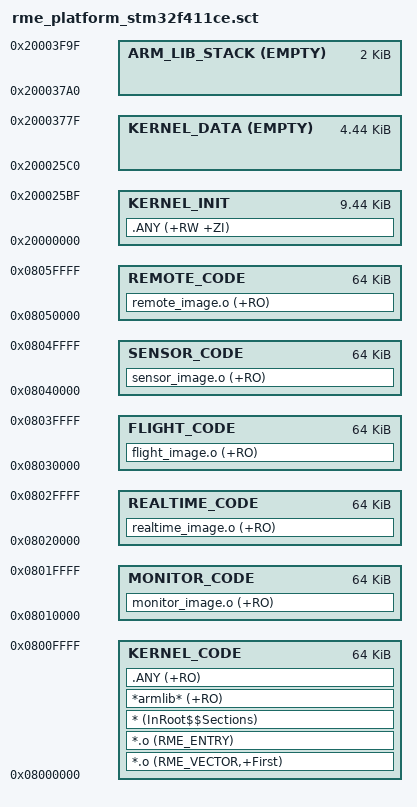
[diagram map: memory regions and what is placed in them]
;******************************************************************************
;Filename    : rme_platform_stm32f411ce.sct
;Author      : The RVM project generator.
;Date        : 21/05/2025 22:33:52
;Licence     : Unlicense; see COPYING for details.
;Description : The scatter file for ARMv7-M layout. This file is intended
;              to be used with STM32F411CE.
;******************************************************************************

;Kernel ***********************************************************************
KERNEL 0x8000000 0x10000
{
    ;Kernel code segment
    KERNEL_CODE 0x8000000 0x10000
    {
        ;The vector table
        *.o                            (RME_VECTOR,+First)
        ;The entry
        *.o                            (RME_ENTRY)
        ;The lib code copying code
        *                              (InRoot$$Sections)
        ;The ARM C library code - all of them is here
        *armlib*                       (+RO)
        ;The kernel code section
        .ANY                           (+RO)
    }

    ;Statically allocated kernel data segment
    KERNEL_INIT 0x20000000 0x25C0
    {
        .ANY                           (+RW +ZI)
    }

    ;Dynamically allocated kernel data segment
    KERNEL_DATA 0x200025C0 EMPTY 0x11C0
    {

    }

    ;Kernel stack segment - required by armlib
    ARM_LIB_STACK 0x200037A0 EMPTY 0x800
    {

    }
}
;End Kernel *******************************************************************

;Monitor **********************************************************************
MONITOR 0x8010000 0x10000
{
    ;Monitor image
    MONITOR_CODE 0x8010000 0x10000
    {
        monitor_image.o                    (+RO)
    }
}
;End Monitor ******************************************************************

;Process **********************************************************************
REALTIME 0x8020000 0x10000
{
    ;Process image
    REALTIME_CODE 0x8020000 0x10000
    {
        realtime_image.o                   (+RO)
    }
}
;End Process ******************************************************************

;Process **********************************************************************
FLIGHT 0x8030000 0x10000
{
    ;Process image
    FLIGHT_CODE 0x8030000 0x10000
    {
        flight_image.o                   (+RO)
    }
}
;End Process ******************************************************************

;Process **********************************************************************
SENSOR 0x8040000 0x10000
{
    ;Process image
    SENSOR_CODE 0x8040000 0x10000
    {
        sensor_image.o                   (+RO)
    }
}
;End Process ******************************************************************

;Process **********************************************************************
REMOTE 0x8050000 0x10000
{
    ;Process image
    REMOTE_CODE 0x8050000 0x10000
    {
        remote_image.o                   (+RO)
    }
}
;End Process ******************************************************************

;End Of File ******************************************************************

;Copyright (C) Evo-Devo Instrum. All rights reserved **************************

